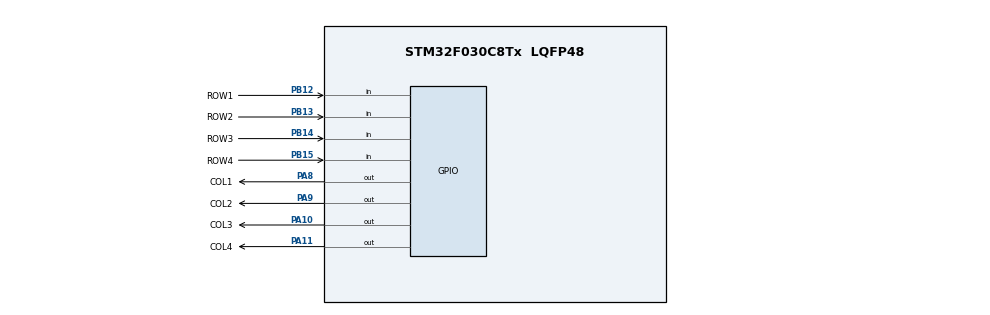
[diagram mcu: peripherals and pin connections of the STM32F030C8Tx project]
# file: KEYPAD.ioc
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Mcu.Family=STM32F0
Mcu.Name=STM32F030C8Tx
Mcu.Package=LQFP48
NVIC.TIM16_IRQn=true\:0\:0\:false\:false\:false\:true\:true\:true
NVIC.TIM17_IRQn=true\:0\:0\:false\:false\:false\:true\:true\:true
PA10.GPIO_Label=COL3
PA10.Signal=GPIO_Output
PA11.GPIO_Label=COL4
PA11.Signal=GPIO_Output
PA13.Mode=Serial_Wire
PA13.Signal=SYS_SWDIO
PA14.Mode=Serial_Wire
PA14.Signal=SYS_SWCLK
PA8.GPIO_Label=COL1
PA8.Signal=GPIO_Output
PA9.GPIO_Label=COL2
PA9.Signal=GPIO_Output
PB12.GPIO_Label=ROW1
PB12.GPIO_PuPd=GPIO_PULLUP
PB12.Signal=GPIO_Input
PB13.GPIO_Label=ROW2
PB13.GPIO_PuPd=GPIO_PULLUP
PB13.Signal=GPIO_Input
PB14.GPIO_Label=ROW3
PB14.GPIO_PuPd=GPIO_PULLUP
PB14.Signal=GPIO_Input
PB15.GPIO_Label=ROW4
PB15.GPIO_PuPd=GPIO_PULLUP
PB15.Signal=GPIO_Input
ProjectManager.HeapSize=0x200
ProjectManager.StackSize=0x400
ProjectManager.TargetToolchain=STM32CubeIDE
RCC.AHBFreq_Value=48000000
RCC.APB1Freq_Value=48000000
RCC.APB1TimFreq_Value=48000000
RCC.HCLKFreq_Value=48000000
RCC.PLLMUL=RCC_PLL_MUL12
RCC.SYSCLKFreq_VALUE=48000000
RCC.SYSCLKSource=RCC_SYSCLKSOURCE_PLLCLK
VP_TIM16_VS_ClockSourceINT.Mode=Enable_Timer
VP_TIM17_VS_ClockSourceINT.Mode=Enable_Timer
board=custom

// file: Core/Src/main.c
/* USER CODE BEGIN Header */
/**
  ******************************************************************************
  * @file           : main.c
  * @brief          : Main program body
  ******************************************************************************
  * @attention
  *
  * Copyright (c) 2024 STMicroelectronics.
  * All rights reserved.
  *
  * This software is licensed under terms that can be found in the LICENSE file
  * in the root directory of this software component.
  * If no LICENSE file comes with this software, it is provided AS-IS.
  *
  ******************************************************************************
  */
/* USER CODE END Header */
#include "main.h"

/* USER CODE BEGIN Includes */
#include "_UserC1.h"

/* USER CODE END Includes */

void SystemClock_Config(void);
static void MX_GPIO_Init(void);
static void MX_TIM16_Init(void);
static void MX_TIM17_Init(void);

int main(void)
{

  /* MCU Configuration--------------------------------------------------------*/

  /* Reset of all peripherals, Initializes the Flash interface and the Systick. */
  LL_APB1_GRP2_EnableClock(LL_APB1_GRP2_PERIPH_SYSCFG);
  LL_APB1_GRP1_EnableClock(LL_APB1_GRP1_PERIPH_PWR);

  /* SysTick_IRQn interrupt configuration */
  NVIC_SetPriority(SysTick_IRQn, 3);

  /* Configure the system clock */
  SystemClock_Config();

  /* Initialize all configured peripherals */
  MX_GPIO_Init();
  MX_TIM16_Init();
  MX_TIM17_Init();
  /* USER CODE BEGIN 2 */
#include "_Main.h"

  /* USER CODE END 2 */

  /* Infinite loop */
  while (1)
  {

    /* USER CODE BEGIN 3 */
#include "_While.h"

  }
  /* USER CODE END 3 */
}

void SystemClock_Config(void)
{
  LL_FLASH_SetLatency(LL_FLASH_LATENCY_1);
  while(LL_FLASH_GetLatency() != LL_FLASH_LATENCY_1)
  {
  }
  LL_RCC_HSI_Enable();

   /* Wait till HSI is ready */
  while(LL_RCC_HSI_IsReady() != 1)
  {

  }
  LL_RCC_HSI_SetCalibTrimming(16);
  LL_RCC_PLL_ConfigDomain_SYS(LL_RCC_PLLSOURCE_HSI_DIV_2, LL_RCC_PLL_MUL_12);
  LL_RCC_PLL_Enable();

   /* Wait till PLL is ready */
  while(LL_RCC_PLL_IsReady() != 1)
  {

  }
  LL_RCC_SetAHBPrescaler(LL_RCC_SYSCLK_DIV_1);
  LL_RCC_SetAPB1Prescaler(LL_RCC_APB1_DIV_1);
  LL_RCC_SetSysClkSource(LL_RCC_SYS_CLKSOURCE_PLL);

   /* Wait till System clock is ready */
  while(LL_RCC_GetSysClkSource() != LL_RCC_SYS_CLKSOURCE_STATUS_PLL)
  {

  }
  LL_Init1msTick(48000000);
  LL_SetSystemCoreClock(48000000);
}

static void MX_TIM16_Init(void)
{

  LL_TIM_InitTypeDef TIM_InitStruct = {0};

  /* Peripheral clock enable */
  LL_APB1_GRP2_EnableClock(LL_APB1_GRP2_PERIPH_TIM16);

  /* TIM16 interrupt Init */
  NVIC_SetPriority(TIM16_IRQn, 0);
  NVIC_EnableIRQ(TIM16_IRQn);

  TIM_InitStruct.Prescaler = 0;
  TIM_InitStruct.CounterMode = LL_TIM_COUNTERMODE_UP;
  TIM_InitStruct.Autoreload = 65535;
  TIM_InitStruct.ClockDivision = LL_TIM_CLOCKDIVISION_DIV1;
  TIM_InitStruct.RepetitionCounter = 0;
  LL_TIM_Init(TIM16, &TIM_InitStruct);
  LL_TIM_DisableARRPreload(TIM16);

}

static void MX_TIM17_Init(void)
{

  LL_TIM_InitTypeDef TIM_InitStruct = {0};

  /* Peripheral clock enable */
  LL_APB1_GRP2_EnableClock(LL_APB1_GRP2_PERIPH_TIM17);

  /* TIM17 interrupt Init */
  NVIC_SetPriority(TIM17_IRQn, 0);
  NVIC_EnableIRQ(TIM17_IRQn);

  TIM_InitStruct.Prescaler = 0;
  TIM_InitStruct.CounterMode = LL_TIM_COUNTERMODE_UP;
  TIM_InitStruct.Autoreload = 65535;
  TIM_InitStruct.ClockDivision = LL_TIM_CLOCKDIVISION_DIV1;
  TIM_InitStruct.RepetitionCounter = 0;
  LL_TIM_Init(TIM17, &TIM_InitStruct);
  LL_TIM_DisableARRPreload(TIM17);

}

static void MX_GPIO_Init(void)
{
  LL_GPIO_InitTypeDef GPIO_InitStruct = {0};

  /* GPIO Ports Clock Enable */
  LL_AHB1_GRP1_EnableClock(LL_AHB1_GRP1_PERIPH_GPIOB);
  LL_AHB1_GRP1_EnableClock(LL_AHB1_GRP1_PERIPH_GPIOA);

  /**/
  LL_GPIO_ResetOutputPin(COL1_GPIO_Port, COL1_Pin);

  /**/
  LL_GPIO_ResetOutputPin(COL2_GPIO_Port, COL2_Pin);

  /**/
  LL_GPIO_ResetOutputPin(COL3_GPIO_Port, COL3_Pin);

  /**/
  LL_GPIO_ResetOutputPin(COL4_GPIO_Port, COL4_Pin);

  /**/
  GPIO_InitStruct.Pin = ROW1_Pin;
  GPIO_InitStruct.Mode = LL_GPIO_MODE_INPUT;
  GPIO_InitStruct.Pull = LL_GPIO_PULL_UP;
  LL_GPIO_Init(ROW1_GPIO_Port, &GPIO_InitStruct);

  /**/
  GPIO_InitStruct.Pin = ROW2_Pin;
  GPIO_InitStruct.Mode = LL_GPIO_MODE_INPUT;
  GPIO_InitStruct.Pull = LL_GPIO_PULL_UP;
  LL_GPIO_Init(ROW2_GPIO_Port, &GPIO_InitStruct);

  /**/
  GPIO_InitStruct.Pin = ROW3_Pin;
  GPIO_InitStruct.Mode = LL_GPIO_MODE_INPUT;
  GPIO_InitStruct.Pull = LL_GPIO_PULL_UP;
  LL_GPIO_Init(ROW3_GPIO_Port, &GPIO_InitStruct);

  /**/
  GPIO_InitStruct.Pin = ROW4_Pin;
  GPIO_InitStruct.Mode = LL_GPIO_MODE_INPUT;
  GPIO_InitStruct.Pull = LL_GPIO_PULL_UP;
  LL_GPIO_Init(ROW4_GPIO_Port, &GPIO_InitStruct);

  /**/
  GPIO_InitStruct.Pin = COL1_Pin;
  GPIO_InitStruct.Mode = LL_GPIO_MODE_OUTPUT;
  GPIO_InitStruct.Speed = LL_GPIO_SPEED_FREQ_LOW;
  GPIO_InitStruct.OutputType = LL_GPIO_OUTPUT_PUSHPULL;
  GPIO_InitStruct.Pull = LL_GPIO_PULL_NO;
  LL_GPIO_Init(COL1_GPIO_Port, &GPIO_InitStruct);

  /**/
  GPIO_InitStruct.Pin = COL2_Pin;
  GPIO_InitStruct.Mode = LL_GPIO_MODE_OUTPUT;
  GPIO_InitStruct.Speed = LL_GPIO_SPEED_FREQ_LOW;
  GPIO_InitStruct.OutputType = LL_GPIO_OUTPUT_PUSHPULL;
  GPIO_InitStruct.Pull = LL_GPIO_PULL_NO;
  LL_GPIO_Init(COL2_GPIO_Port, &GPIO_InitStruct);

  /**/
  GPIO_InitStruct.Pin = COL3_Pin;
  GPIO_InitStruct.Mode = LL_GPIO_MODE_OUTPUT;
  GPIO_InitStruct.Speed = LL_GPIO_SPEED_FREQ_LOW;
  GPIO_InitStruct.OutputType = LL_GPIO_OUTPUT_PUSHPULL;
  GPIO_InitStruct.Pull = LL_GPIO_PULL_NO;
  LL_GPIO_Init(COL3_GPIO_Port, &GPIO_InitStruct);

  /**/
  GPIO_InitStruct.Pin = COL4_Pin;
  GPIO_InitStruct.Mode = LL_GPIO_MODE_OUTPUT;
  GPIO_InitStruct.Speed = LL_GPIO_SPEED_FREQ_LOW;
  GPIO_InitStruct.OutputType = LL_GPIO_OUTPUT_PUSHPULL;
  GPIO_InitStruct.Pull = LL_GPIO_PULL_NO;
  LL_GPIO_Init(COL4_GPIO_Port, &GPIO_InitStruct);

}

void Error_Handler(void)
{
  __disable_irq();
  while (1)
  {
  }
}
